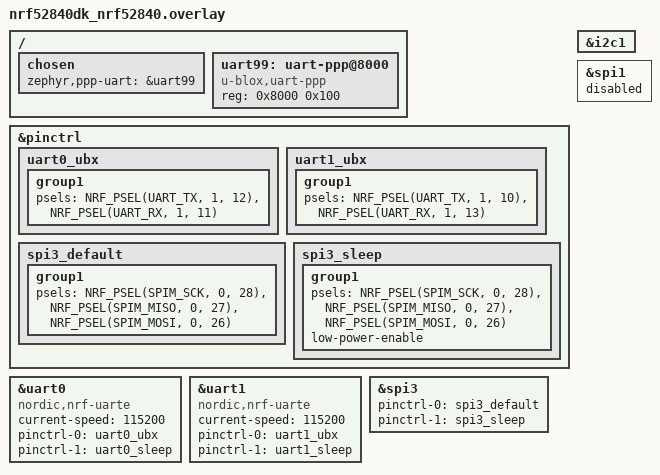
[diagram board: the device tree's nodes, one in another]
/* This configuration is specifically modified for the tests as run on a NRF52840 board wired in the u-blox test system. */
/* For default settings, refer to the file of the same name in the boards/arm directory of Zephyr. */

&pinctrl {
	uart0_ubx: uart0_ubx {
		group1 {
			psels = <NRF_PSEL(UART_TX, 1, 12)>,
			        <NRF_PSEL(UART_RX, 1, 11)>;
		};
	};

	uart1_ubx: uart1_ubx {
		group1 {
			psels = <NRF_PSEL(UART_TX, 1, 10)>,
			    <NRF_PSEL(UART_RX, 1, 13)>;
		};
	};

	spi3_default: spi3_default {
		group1 {
			psels = <NRF_PSEL(SPIM_SCK, 0, 28)>,
				<NRF_PSEL(SPIM_MISO, 0, 27)>,
				<NRF_PSEL(SPIM_MOSI, 0, 26)>;
		};
	};

	spi3_sleep: spi3_sleep {
		group1 {
			psels = <NRF_PSEL(SPIM_SCK, 0, 28)>,
				<NRF_PSEL(SPIM_MISO, 0, 27)>,
				<NRF_PSEL(SPIM_MOSI, 0, 26)>;
			low-power-enable;
		};
	};

};

&uart0 {
	compatible = "nordic,nrf-uarte";
	status = "okay";
	current-speed = <115200>;
	pinctrl-0 = <&uart0_ubx>;
	pinctrl-1 = <&uart0_sleep>;
	pinctrl-names = "default", "sleep";
};

&uart1 {
	compatible = "nordic,nrf-uarte";
	status = "okay";
	current-speed = <115200>;
	pinctrl-0 = <&uart1_ubx>;
	pinctrl-1 = <&uart1_sleep>;
	pinctrl-names = "default", "sleep";
};

&i2c1 {
	status = "okay";
	/* Otherwise board default settings are good. */
};

/* When SPI is enabled we need to remove SPI1 to continue to have I2C1, otherwise the main .dts file brings it in. */
&spi1 {
	status = "disabled";
};

&spi3 {
	status = "okay";
	pinctrl-0 = <&spi3_default>;
	pinctrl-1 = <&spi3_sleep>;
	pinctrl-names = "default", "sleep";
};

/* Required for PPP-level integration with ubxlib to work */
/ { // The leading / indicates that we're in the root section
    // This chooses uart instance 99 to be the zephyr,ppp-uart that ppp.c wants
    chosen {
        zephyr,ppp-uart = &uart99;
    };

    // This creates instance 99 of a uart that we will give to zephyr,ppp-uart
    uart99: uart-ppp@8000 { // The "8000" here is irrelevant but required for Zephyr to work
        compatible = "u-blox,uart-ppp"; // The important part: this is an instance of u-blox,uart-ppp
        reg = <0x8000 0x100>; // This is irrelevant but required for Zephyr to work
        status = "okay"; // Zephyr boiler-plate
    };
};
